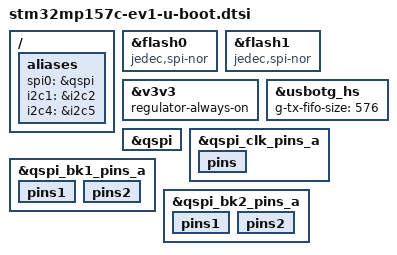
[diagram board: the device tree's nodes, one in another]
// SPDX-License-Identifier: GPL-2.0+ OR BSD-3-Clause
/*
 * Copyright : STMicroelectronics 2018
 */

#include "stm32mp157c-ed1-u-boot.dtsi"

/ {
	aliases {
		spi0 = &qspi;
		i2c1 = &i2c2;
		i2c4 = &i2c5;
	};
};

&flash0 {
	compatible = "jedec,spi-nor";
};

&flash1 {
	compatible = "jedec,spi-nor";
};

&v3v3 {
	regulator-always-on;
};

&usbotg_hs {
	g-tx-fifo-size = <576>;
};

/* SPL part **************************************/
&qspi {
	u-boot,dm-spl;
};

&qspi_clk_pins_a {
	u-boot,dm-spl;
	pins {
		u-boot,dm-spl;
	};
};

&qspi_bk1_pins_a {
	u-boot,dm-spl;
	pins1 {
		u-boot,dm-spl;
	};
	pins2 {
		u-boot,dm-spl;
	};
};

&qspi_bk2_pins_a {
	u-boot,dm-spl;
	pins1 {
		u-boot,dm-spl;
	};
	pins2 {
		u-boot,dm-spl;
	};
};

&flash0 {
	u-boot,dm-spl;
};

